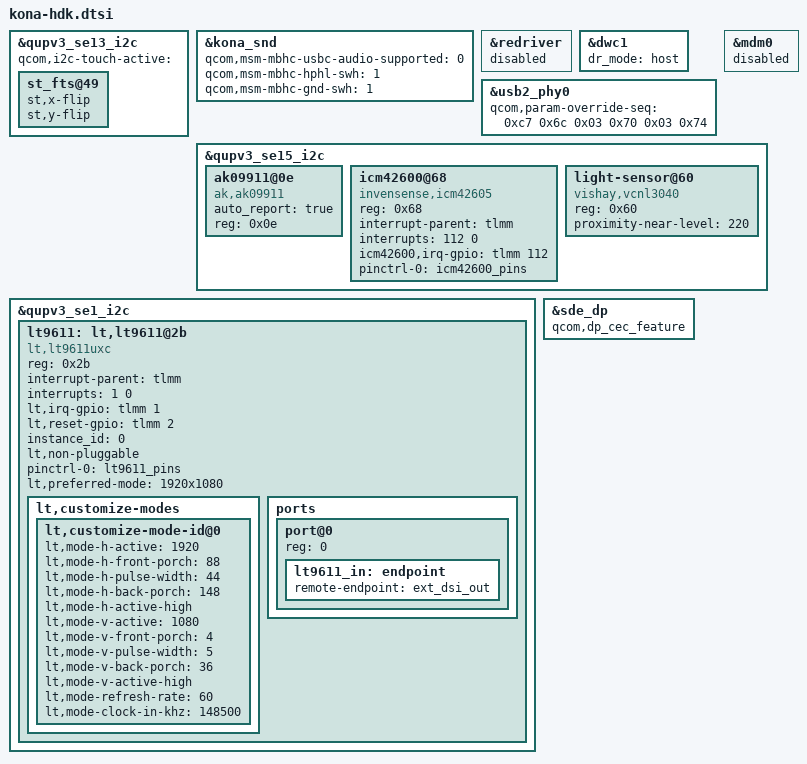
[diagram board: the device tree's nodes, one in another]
#include "kona-qrd.dtsi"

&qupv3_se13_i2c {
	status = "ok";
	qcom,i2c-touch-active = "";

	st_fts@49 {
		st,x-flip;
		st,y-flip;
	};
};

&kona_snd {
	qcom,msm-mbhc-usbc-audio-supported = <0>;
	qcom,msm-mbhc-hphl-swh = <1>;
	qcom,msm-mbhc-gnd-swh = <1>;
};

&redriver {
	status = "disabled";
};

&dwc1 {
	dr_mode = "host";
};

&usb2_phy0 {
	qcom,param-override-seq =
		<0xc7 0x6c
		0x03 0x70
		0x03 0x74>;
};

&mdm0 {
	status = "disabled";
};

/* ACHEUL */
&qupv3_se15_i2c {
	#address-cells = <1>;
	#size-cells = <0>;
	status = "ok";

    ak09911@0e {
	    status = "ok";
	    compatible = "ak,ak09911";
        auto_report = "true";
	    reg = <0x0e>;
    };

    /* GPIO 112 == INT1
       GPIO 113 == INT2 */

    icm42600@68 {
	    status = "ok";
        compatible = "invensense,icm42605";
        reg = <0x68>;
        interrupt-parent = <&tlmm>;
        interrupts = <112 0>;
        interrupt-names = "icm42600_irq";
        icm42600,irq-gpio = <&tlmm 112 0x0>;
        pinctrl-names = "default";
        pinctrl-0 = <&icm42600_pins>;

    };

    light-sensor@60 {
	    status = "ok";
        compatible = "vishay,vcnl3040";
        reg = <0x60>;
        proximity-near-level = <220>;
    };

#include "smb1355.dtsi"
};

&qupv3_se1_i2c {
	status = "ok";
	lt9611: lt,lt9611@2b {
		compatible = "lt,lt9611uxc";
		reg = <0x2b>;
		interrupt-parent = <&tlmm>;
		interrupts = <1 0>;
		interrupt-names = "lt_irq";
		lt,irq-gpio = <&tlmm 1 0x0>;
		lt,reset-gpio = <&tlmm 2 0x0>;
		instance_id = <0>;
		lt,non-pluggable;

		pinctrl-names = "default";
		pinctrl-0 = <&lt9611_pins>;

		lt,preferred-mode = "1920x1080";

		lt,customize-modes {
			lt,customize-mode-id@0 {
				lt,mode-h-active = <1920>;
				lt,mode-h-front-porch = <88>;
				lt,mode-h-pulse-width = <44>;
				lt,mode-h-back-porch = <148>;
				lt,mode-h-active-high;
				lt,mode-v-active = <1080>;
				lt,mode-v-front-porch = <4>;
				lt,mode-v-pulse-width = <5>;
				lt,mode-v-back-porch = <36>;
				lt,mode-v-active-high;
				lt,mode-refresh-rate = <60>;
				lt,mode-clock-in-khz = <148500>;
			};
		};

		ports {
			#address-cells = <1>;
			#size-cells = <0>;

			port@0 {
				reg = <0>;
				lt9611_in: endpoint {
					remote-endpoint = <&ext_dsi_out>;
				};
			};

		};
	};
};

/*
ACHEUL
&sde_dsi {
	qcom,dsi-default-panel = <&dsi_ext_bridge_1080p>;

	ports {
		#address-cells = <1>;
		#size-cells = <0>;

		port@0 {
			reg = <0>;
			ext_dsi_out: endpoint {
				remote-endpoint = <&lt9611_in>;
			};
		};
	};
};
*/

&sde_dp {
	qcom,dp_cec_feature;
};
